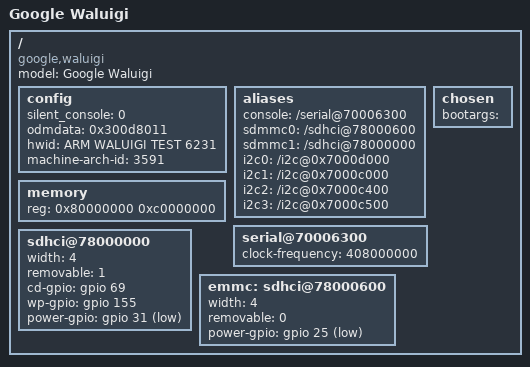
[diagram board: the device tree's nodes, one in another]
/dts-v1/;

/memreserve/ 0x1c000000 0x04000000;
/include/ "tegra30.dtsi"

/ {
	model = "Google Waluigi";
	compatible = "google,waluigi", "nvidia,tegra30";

	config {
		silent_console = <0>;
		odmdata = <0x300d8011>;
		hwid = "ARM WALUIGI TEST 6231";
		machine-arch-id = <3591>;
	};

	aliases {
		console = "/serial@70006300";

		sdmmc0 = "/sdhci@78000600";
		sdmmc1 = "/sdhci@78000000";

		i2c0 = "/i2c@0x7000d000";
		i2c1 = "/i2c@0x7000c000";
		i2c2 = "/i2c@0x7000c400";
		i2c3 = "/i2c@0x7000c500";
	};

	chosen {
		bootargs = "";
	};

	memory {
		device_type = "memory";
		reg = <0x80000000 0xc0000000>;
	};

	serial@70006300 {
		status = "ok";
		/*
		 * TBD - use CONFIG_SYS_PLLP_BASE_IS_408MHZ somehow here.
		 * Currently I put this back to 216MHz in fdt_decode.c
		 */
		clock-frequency = <408000000>;
	};

	/* External SD card - SDMMC1 */
	sdhci@78000000 {
		status = "ok";
		width = <4>;	/* width of SDIO port */
		removable = <1>;
		/* Parameter 3 bit 0:1=output, 0=input; bit 1:1=high, 0=low */
		cd-gpio = <&gpio 69 0>; /* card detect, GMI_IORDY => I.05 */
		wp-gpio = <&gpio 155 0>; /* write protect, VI_D11 => T.03 */
		power-gpio = <&gpio 31 3>; /* power enable, VI_HSYNC => D.07 */
	};

	/* Internal eMMC - SDMMC4 */
	emmc: sdhci@78000600 {
		status = "ok";
		width = <4>;	/* width of SDIO port */
		removable = <0>;
		power-gpio = <&gpio 25 3>; /* power enable, gpio PD1 */
	};

};
